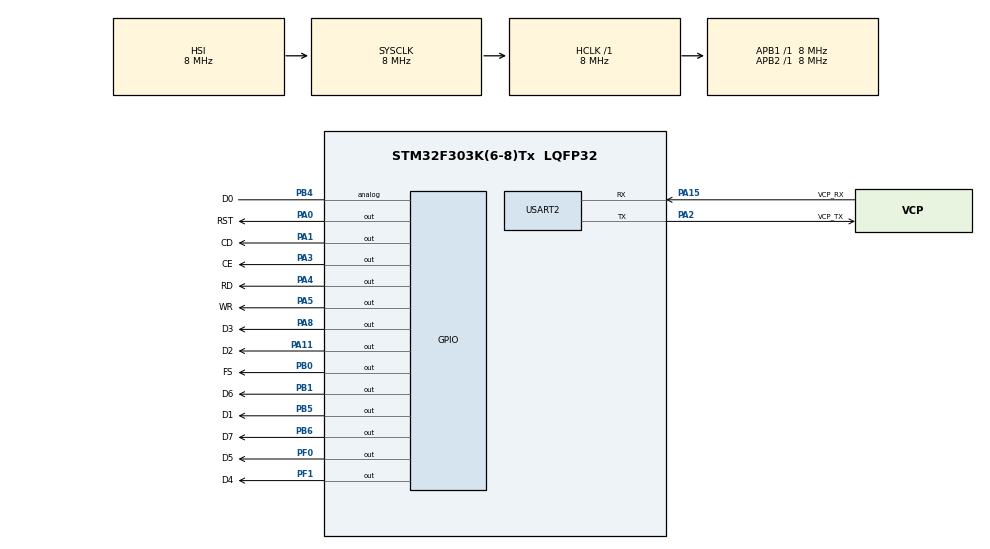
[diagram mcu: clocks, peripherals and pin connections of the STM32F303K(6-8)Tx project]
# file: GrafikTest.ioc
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Mcu.Family=STM32F3
Mcu.Name=STM32F303K(6-8)Tx
Mcu.Package=LQFP32
NVIC.PriorityGroup=NVIC_PRIORITYGROUP_4
PA0.GPIO_Label=RST
PA0.Signal=GPIO_Output
PA1.GPIO_Label=CD
PA1.Signal=GPIO_Output
PA11.GPIO_Label=D2
PA11.Signal=GPIO_Output
PA13.GPIO_Label=SWDIO
PA13.Mode=Serial_Wire
PA13.Signal=SYS_JTMS-SWDIO
PA14.GPIO_Label=SWCLK
PA14.Mode=Serial_Wire
PA14.Signal=SYS_JTCK-SWCLK
PA15.GPIO_Label=VCP_RX
PA15.Mode=Asynchronous
PA15.Signal=USART2_RX
PA2.GPIO_Label=VCP_TX
PA2.Mode=Asynchronous
PA2.Signal=USART2_TX
PA3.GPIO_Label=CE
PA3.Signal=GPIO_Output
PA4.GPIO_Label=RD
PA4.Signal=GPIO_Output
PA5.GPIO_Label=WR
PA5.Signal=GPIO_Output
PA8.GPIO_Label=D3
PA8.Signal=GPIO_Output
PB0.GPIO_Label=FS
PB0.Signal=GPIO_Output
PB1.GPIO_Label=D6
PB1.Signal=GPIO_Output
PB4.GPIO_Label=D0
PB4.Signal=GPIO_Analog
PB5.GPIO_Label=D1
PB5.Signal=GPIO_Output
PB6.GPIO_Label=D7
PB6.Signal=GPIO_Output
PF0\ /\ OSC_IN.GPIO_Label=D5
PF0\ /\ OSC_IN.Signal=GPIO_Output
PF1\ /\ OSC_OUT.GPIO_Label=D4
PF1\ /\ OSC_OUT.Signal=GPIO_Output
ProjectManager.HeapSize=0x200
ProjectManager.StackSize=0x400
ProjectManager.TargetToolchain=STM32CubeIDE
RCC.AHBFreq_Value=8000000
RCC.APB1Freq_Value=8000000
RCC.APB2Freq_Value=8000000
RCC.CortexFreq_Value=8000000
RCC.HSE_VALUE=8000000
RCC.HSI_VALUE=8000000
RCC.SYSCLKFreq_VALUE=8000000
USART2.VirtualMode-Asynchronous=VM_ASYNC
board=NUCLEO-F303K8

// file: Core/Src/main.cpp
/* USER CODE BEGIN Header */
/**
  ******************************************************************************
  * @file           : main.c
  * @brief          : Main program body
  ******************************************************************************
  * @attention
  *
  * <h2><center>&copy; Copyright (c) 2020 STMicroelectronics.
  * All rights reserved.</center></h2>
  *
  * This software component is licensed by ST under BSD 3-Clause license,
  * the "License"; You may not use this file except in compliance with the
  * License. You may obtain a copy of the License at:
  *                        opensource.org/licenses/BSD-3-Clause
  *
  ******************************************************************************
  */
/* USER CODE END Header */

#include "main.h"
#include "usart.h"
#include "gpio.h"

/* USER CODE BEGIN Includes */
#include "AppMain/AppMain.h"
/* USER CODE END Includes */

/* USER CODE BEGIN PTD */
static AppMain appMain;
/* USER CODE END PTD */

void SystemClock_Config(void);

int main(void)
{

  /* MCU Configuration--------------------------------------------------------*/

  /* Reset of all peripherals, Initializes the Flash interface and the Systick. */
  HAL_Init();

  /* Configure the system clock */
  SystemClock_Config();

  /* Initialize all configured peripherals */
  MX_GPIO_Init();
  MX_USART2_UART_Init();
  /* USER CODE BEGIN 2 */
appMain.main();
  /* USER CODE END 2 */

  /* Infinite loop */
  while (1)
  {

  }
}

void SystemClock_Config(void)
{
  RCC_OscInitTypeDef RCC_OscInitStruct = {0};
  RCC_ClkInitTypeDef RCC_ClkInitStruct = {0};

  /** Initializes the CPU, AHB and APB busses clocks
  */
  RCC_OscInitStruct.OscillatorType = RCC_OSCILLATORTYPE_HSI;
  RCC_OscInitStruct.HSIState = RCC_HSI_ON;
  RCC_OscInitStruct.HSICalibrationValue = RCC_HSICALIBRATION_DEFAULT;
  RCC_OscInitStruct.PLL.PLLState = RCC_PLL_NONE;
  if (HAL_RCC_OscConfig(&RCC_OscInitStruct) != HAL_OK)
  {
    Error_Handler();
  }
  /** Initializes the CPU, AHB and APB busses clocks
  */
  RCC_ClkInitStruct.ClockType = RCC_CLOCKTYPE_HCLK|RCC_CLOCKTYPE_SYSCLK
                              |RCC_CLOCKTYPE_PCLK1|RCC_CLOCKTYPE_PCLK2;
  RCC_ClkInitStruct.SYSCLKSource = RCC_SYSCLKSOURCE_HSI;
  RCC_ClkInitStruct.AHBCLKDivider = RCC_SYSCLK_DIV1;
  RCC_ClkInitStruct.APB1CLKDivider = RCC_HCLK_DIV1;
  RCC_ClkInitStruct.APB2CLKDivider = RCC_HCLK_DIV1;

  if (HAL_RCC_ClockConfig(&RCC_ClkInitStruct, FLASH_LATENCY_0) != HAL_OK)
  {
    Error_Handler();
  }
}

void Error_Handler(void)
{
}

/************************ (C) COPYRIGHT STMicroelectronics *****END OF FILE****/
